# ESP32S31_RADIO register map
Vendor: Espressif; Series: ESP32-S31; File version: 3.52
Registers are 32-bit, read-write, no defined reset value unless marked. A register's access mark holds for its fields unless they carry their own. Offsets are from the block's base; [hi:lo] are bit positions.

## WIFI_MAC_HE_INIT_PREFIX — Complete hal_he_init prefix through hal_init_tb_tx, stopping immediately before hal_init_tx_pwr. Twenty-two separate RMW edges and one final synchronization/status read.
Base 0x20104048
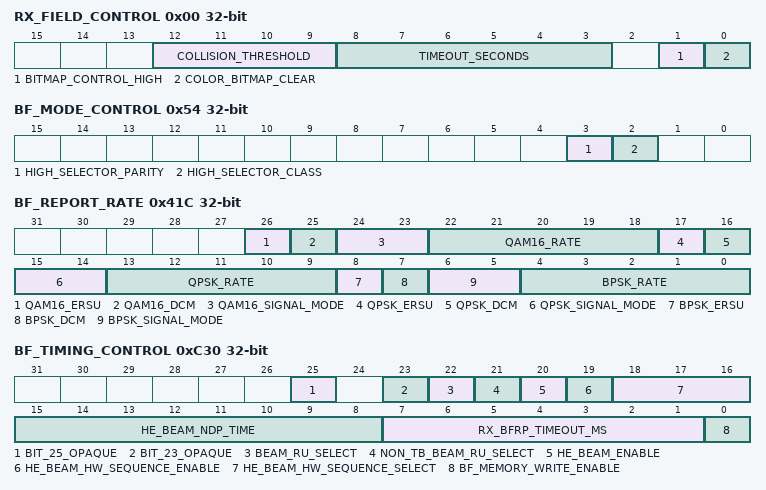
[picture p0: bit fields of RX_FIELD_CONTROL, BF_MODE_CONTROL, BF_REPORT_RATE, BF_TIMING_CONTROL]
0x00 RX_FIELD_CONTROL — Project-assigned name. Canonical RX_HE_BSS_COLOR_CONF word. Complete dbg_read_color_collision names the fields; the HE init parent replaces TIMEOUT_SECONDS bits 8:3 with 0x3c. HE Operation programming sets COLOR_BITMAP_CLEAR to clear the accumulated BSS-color collision bitmap.
  [12:9] COLLISION_THRESHOLD — Project-assigned name.
  [8:3] TIMEOUT_SECONDS — Project-assigned name.
  [1] BITMAP_CONTROL_HIGH — Project-assigned name. High bit of the two-bit BITMAP diagnostic printed by complete dbg_read_color_collision. No independent write-side meaning is currently claimed.
  [0] COLOR_BITMAP_CLEAR — Project-assigned name. COLOR_BITMAP_CLR in complete dbg_read_color_collision. HE Operation programming sets this bit to clear the accumulated BSS-color collision bitmap.
0x54 BF_MODE_CONTROL — Project-assigned name. Complete hal_init_bf clears bit two, then sets bit three through a separate fresh-read RMW. Complete esp_test_bf_set_feedback proves these same physical fields are the high-selector class and parity controls for its feedback modes; this is one canonical register identity rather than an address alias.
  [3] HIGH_SELECTOR_PARITY — Project-assigned name. For test feedback selector values eight through fourteen, receives selector bit zero; selectors fifteen and sixteen clear it. Complete hal_init_bf sets it.
  [2] HIGH_SELECTOR_CLASS — Project-assigned name. For test feedback selector values eight through fourteen, set exactly when selector is greater than nine. Complete hal_init_bf clears it.
0x41C BF_REPORT_RATE — Project-assigned name. Three independently published beamforming-report profiles selected for BPSK, QPSK and 16-QAM. Complete libpp[hal_mac_ctl.o]::hal_he_set_bf_report_rate(1,0x10,0,0) writes signal mode one, normalized rate zero, DCM false and ER-SU false into the 16-QAM, QPSK and BPSK profiles in that order.
  [26] QAM16_ERSU — Project-assigned name.
  [25] QAM16_DCM — Project-assigned name.
  [24:23] QAM16_SIGNAL_MODE — Project-assigned name.
  [22:18] QAM16_RATE — Project-assigned name.
  [17] QPSK_ERSU — Project-assigned name.
  [16] QPSK_DCM — Project-assigned name.
  [15:14] QPSK_SIGNAL_MODE — Project-assigned name.
  [13:9] QPSK_RATE — Project-assigned name.
  [8] BPSK_ERSU — Project-assigned name.
  [7] BPSK_DCM — Project-assigned name.
  [6:5] BPSK_SIGNAL_MODE — Project-assigned name.
  [4:0] BPSK_RATE — Project-assigned name.
0x434 BF_VECTOR_CONTROL — Project-assigned name. Complete hal_init_bf replaces bits 23:12 with 0x801.
  [23:12] BITS_12_23_OPAQUE — Opaque: meaning not established.
0x438 BF_ENABLE — Project-assigned name. Complete hal_init_bf sets bit 31.
  [31] BIT_31_OPAQUE — Opaque: meaning not established.
0xBE4 PARENT_ENABLE — Project-assigned name. Parent sets bit 12 before trigger-based TX init. Complete print_isr_regs independently names this same physical word WDEV_INT1_ENABLE. This is one canonical register with two observed roles, not two peripheral owners.
  [12] BIT_12_OPAQUE — Opaque: meaning not established.
0xBE8 INTERRUPT_1_RAW — Project-assigned name. WDEV_INT1_RAW snapshot read by print_isr_regs. Complete hal_disable_mac writes zero after masking the primary MAC interrupt bank.
  [31:0] EVENTS — Project-assigned name.
0xBEC INTERRUPT_1_STATUS ro — Project-assigned name. WDEV_INT1_STATUS diagnostic snapshot read by complete print_isr_regs.
  [31:0] EVENTS — Project-assigned name.
0xBF0 INTERRUPT_1_CLEAR write-1-clears — Project-assigned name. Complete libpp[hal_mac_ctl.o]::hal_mac_interrupt_clr_bsscolor sets bit 12 through a fresh-read RMW to acknowledge the secondary BSS-color event.
  [12] BSS_COLOR — Project-assigned name.
0xC30 BF_TIMING_CONTROL — Project-assigned name. Seven ordered RMWs in complete hal_init_bf. Complete dbg_read_rx_misc supplies the beamforming field names through its WDEVBEAMFORMCONF decoder. Complete dbg_disable_report_cbf independently proves the write polarity of HE_BEAM_ENABLE bit 20. Complete esp_test_get_csi_dump_cfg supplies the more specific RXBFRPTO_MS name for bits 7:1.
  [25] BIT_25_OPAQUE — Opaque: meaning not established.
  [23] BIT_23_OPAQUE — Opaque: meaning not established.
  [22] BEAM_RU_SELECT — Project-assigned name.
  [21] NON_TB_BEAM_RU_SELECT — Project-assigned name.
  [20] HE_BEAM_ENABLE — Project-assigned name. Complete dbg_read_rx_misc names bit 20 HE_BEAM_ENA. Complete dbg_disable_report_cbf clears it for a nonzero disable argument and sets it for zero, connecting the general hardware label to compressed-beamforming-report output.
  [19] HE_BEAM_HW_SEQUENCE_ENABLE — Project-assigned name.
  [18:16] HE_BEAM_HW_SEQUENCE_SELECT — Project-assigned name.
  [15:8] HE_BEAM_NDP_TIME — Project-assigned name.
  [7:1] RX_BFRP_TIMEOUT_MS — Project-assigned name. Vendor test getter names bits 7:1 RXBFRPTO_MS.
  [0] BF_MEMORY_WRITE_ENABLE — Project-assigned name.
0xD9C BF_HIGH_IMAGE — Project-assigned name. Complete hal_init_bf replaces bits 31:20 with 0x690.
  [31:20] BITS_20_31_OPAQUE — Opaque: meaning not established.
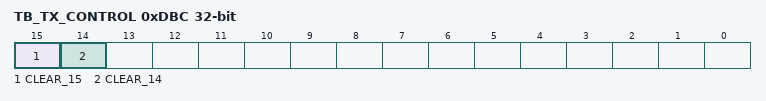
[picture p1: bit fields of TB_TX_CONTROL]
0xDBC TB_TX_CONTROL — Project-assigned name. Complete hal_init_tb_tx clears bit 15, then bit 14 through a separate fresh-read RMW.
  [15] CLEAR_15 — Project-assigned name.
  [14] CLEAR_14 — Project-assigned name.
